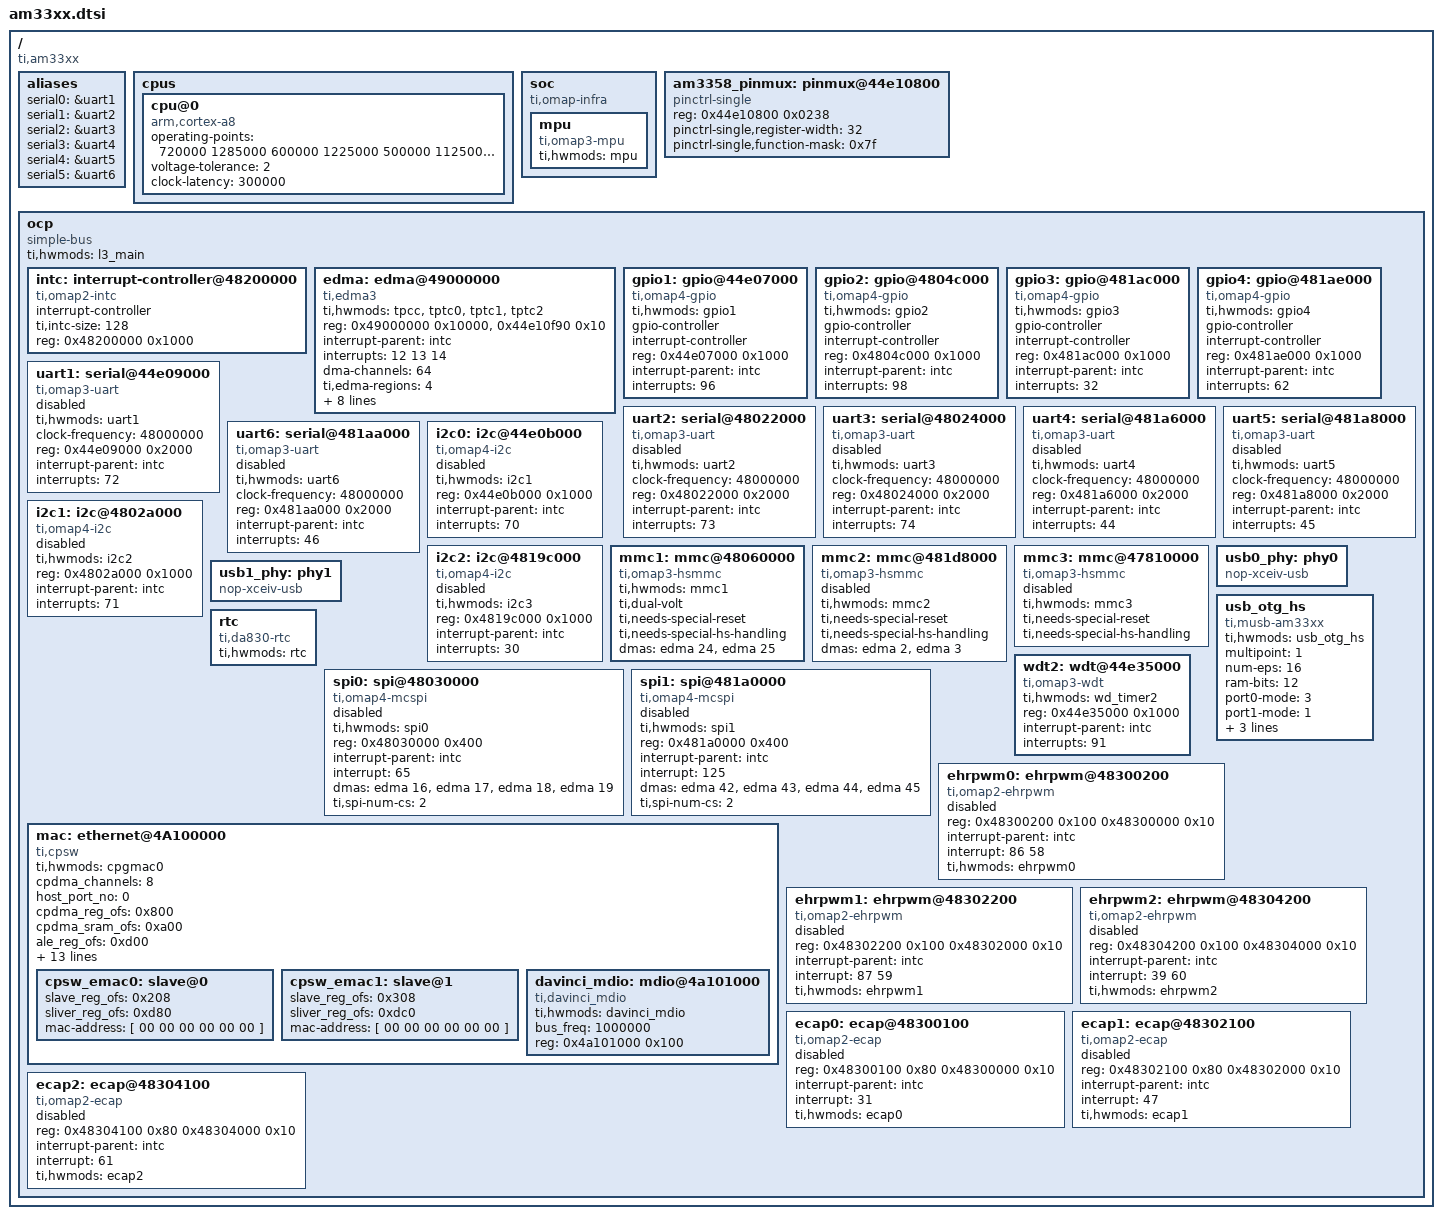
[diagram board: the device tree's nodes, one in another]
/*
 * Device Tree Source for AM33XX SoC
 *
 * Copyright (C) 2012 Texas Instruments Incorporated - http://www.ti.com/
 *
 * This file is licensed under the terms of the GNU General Public License
 * version 2.  This program is licensed "as is" without any warranty of any
 * kind, whether express or implied.
 */

/include/ "skeleton.dtsi"

/ {
	compatible = "ti,am33xx";

	aliases {
		serial0 = &uart1;
		serial1 = &uart2;
		serial2 = &uart3;
		serial3 = &uart4;
		serial4 = &uart5;
		serial5 = &uart6;
	};

	cpus {
		cpu@0 {
			compatible = "arm,cortex-a8";

			/*
			 * To consider voltage drop between PMIC and SoC,
			 * tolerance value is reduced to 2% from 4% and
			 * voltage value is increased as a precaution.
			 */
			operating-points = <
				/* kHz    uV */
				720000  1285000
				600000  1225000
				500000  1125000
				275000  1125000
			>;
			voltage-tolerance = <2>; /* 2 percentage */
			clock-latency = <300000>; /* From omap-cpufreq driver */
		};
	};

	/*
	 * The soc node represents the soc top level view. It is uses for IPs
	 * that are not memory mapped in the MPU view or for the MPU itself.
	 */
	soc {
		compatible = "ti,omap-infra";
		mpu {
			compatible = "ti,omap3-mpu";
			ti,hwmods = "mpu";
		};
	};

	am3358_pinmux: pinmux@44e10800 {
		compatible = "pinctrl-single";
		reg = <0x44e10800 0x0238>;
		#address-cells = <1>;
		#size-cells = <0>;
		pinctrl-single,register-width = <32>;
		pinctrl-single,function-mask = <0x7f>;
	};

	/*
	 * XXX: Use a flat representation of the AM33XX interconnect.
	 * The real AM33XX interconnect network is quite complex.Since
	 * that will not bring real advantage to represent that in DT
	 * for the moment, just use a fake OCP bus entry to represent
	 * the whole bus hierarchy.
	 */
	ocp {
		compatible = "simple-bus";
		#address-cells = <1>;
		#size-cells = <1>;
		ranges;
		ti,hwmods = "l3_main";

		intc: interrupt-controller@48200000 {
			compatible = "ti,omap2-intc";
			interrupt-controller;
			#interrupt-cells = <1>;
			ti,intc-size = <128>;
			reg = <0x48200000 0x1000>;
		};

		edma: edma@49000000 {
			compatible = "ti,edma3";
			ti,hwmods = "tpcc", "tptc0", "tptc1", "tptc2";
			reg =	<0x49000000 0x10000>,
				<0x44e10f90 0x10>;
			interrupt-parent = <&intc>;
			interrupts = <12 13 14>;
			#dma-cells = <1>;
			dma-channels = <64>;
			ti,edma-regions = <4>;
			ti,edma-slots = <256>;
			ti,edma-reserved-channels = <0  2
						     14 2
						     26 6
						     48 4
						     56 8>;
			ti,edma-reserved-slots = <0  2
						  14 2
						  26 6
						  48 4
						  56 8
						  64 127>;
			ti,edma-queue-tc-map = <0 0
						1 1
						2 2>;
			ti,edma-queue-priority-map = <0 0
						      1 1
						      2 2>;
			ti,edma-default-queue = <0>;
		};

		gpio1: gpio@44e07000 {
			compatible = "ti,omap4-gpio";
			ti,hwmods = "gpio1";
			gpio-controller;
			#gpio-cells = <2>;
			interrupt-controller;
			#interrupt-cells = <1>;
			reg = <0x44e07000 0x1000>;
			interrupt-parent = <&intc>;
			interrupts = <96>;
		};

		gpio2: gpio@4804c000 {
			compatible = "ti,omap4-gpio";
			ti,hwmods = "gpio2";
			gpio-controller;
			#gpio-cells = <2>;
			interrupt-controller;
			#interrupt-cells = <1>;
			reg = <0x4804c000 0x1000>;
			interrupt-parent = <&intc>;
			interrupts = <98>;
		};

		gpio3: gpio@481ac000 {
			compatible = "ti,omap4-gpio";
			ti,hwmods = "gpio3";
			gpio-controller;
			#gpio-cells = <2>;
			interrupt-controller;
			#interrupt-cells = <1>;
			reg = <0x481ac000 0x1000>;
			interrupt-parent = <&intc>;
			interrupts = <32>;
		};

		gpio4: gpio@481ae000 {
			compatible = "ti,omap4-gpio";
			ti,hwmods = "gpio4";
			gpio-controller;
			#gpio-cells = <2>;
			interrupt-controller;
			#interrupt-cells = <1>;
			reg = <0x481ae000 0x1000>;
			interrupt-parent = <&intc>;
			interrupts = <62>;
		};

		uart1: serial@44e09000 {
			compatible = "ti,omap3-uart";
			ti,hwmods = "uart1";
			clock-frequency = <48000000>;
			reg = <0x44e09000 0x2000>;
			interrupt-parent = <&intc>;
			interrupts = <72>;
			status = "disabled";
		};

		uart2: serial@48022000 {
			compatible = "ti,omap3-uart";
			ti,hwmods = "uart2";
			clock-frequency = <48000000>;
			reg = <0x48022000 0x2000>;
			interrupt-parent = <&intc>;
			interrupts = <73>;
			status = "disabled";
		};

		uart3: serial@48024000 {
			compatible = "ti,omap3-uart";
			ti,hwmods = "uart3";
			clock-frequency = <48000000>;
			reg = <0x48024000 0x2000>;
			interrupt-parent = <&intc>;
			interrupts = <74>;
			status = "disabled";
		};

		uart4: serial@481a6000 {
			compatible = "ti,omap3-uart";
			ti,hwmods = "uart4";
			clock-frequency = <48000000>;
			reg = <0x481a6000 0x2000>;
			interrupt-parent = <&intc>;
			interrupts = <44>;
			status = "disabled";
		};

		uart5: serial@481a8000 {
			compatible = "ti,omap3-uart";
			ti,hwmods = "uart5";
			clock-frequency = <48000000>;
			reg = <0x481a8000 0x2000>;
			interrupt-parent = <&intc>;
			interrupts = <45>;
			status = "disabled";
		};

		uart6: serial@481aa000 {
			compatible = "ti,omap3-uart";
			ti,hwmods = "uart6";
			clock-frequency = <48000000>;
			reg = <0x481aa000 0x2000>;
			interrupt-parent = <&intc>;
			interrupts = <46>;
			status = "disabled";
		};

		i2c0: i2c@44e0b000 {
			compatible = "ti,omap4-i2c";
			#address-cells = <1>;
			#size-cells = <0>;
			ti,hwmods = "i2c1";	/* TODO: Fix hwmod */
			reg = <0x44e0b000 0x1000>;
			interrupt-parent = <&intc>;
			interrupts = <70>;
			status = "disabled";
		};

		i2c1: i2c@4802a000 {
			compatible = "ti,omap4-i2c";
			#address-cells = <1>;
			#size-cells = <0>;
			ti,hwmods = "i2c2";	/* TODO: Fix hwmod */
			reg = <0x4802a000 0x1000>;
			interrupt-parent = <&intc>;
			interrupts = <71>;
			status = "disabled";
		};

		i2c2: i2c@4819c000 {
			compatible = "ti,omap4-i2c";
			#address-cells = <1>;
			#size-cells = <0>;
			ti,hwmods = "i2c3";	/* TODO: Fix hwmod */
			reg = <0x4819c000 0x1000>;
			interrupt-parent = <&intc>;
			interrupts = <30>;
			status = "disabled";
		};

		mmc1: mmc@48060000 {
			compatible = "ti,omap3-hsmmc";
			ti,hwmods = "mmc1";
			ti,dual-volt;
			ti,needs-special-reset;
			ti,needs-special-hs-handling;
			dmas = <&edma 24
				&edma 25>;
			dma-names = "tx", "rx";
		};

		mmc2: mmc@481d8000 {
			compatible = "ti,omap3-hsmmc";
			ti,hwmods = "mmc2";
			ti,needs-special-reset;
			ti,needs-special-hs-handling;
			dmas = <&edma 2
				&edma 3>;
			dma-names = "tx", "rx";
			status = "disabled";
		};

		mmc3: mmc@47810000 {
			compatible = "ti,omap3-hsmmc";
			ti,hwmods = "mmc3";
			ti,needs-special-reset;
			ti,needs-special-hs-handling;
			status = "disabled";
		};

		usb0_phy: phy0 {
			compatible = "nop-xceiv-usb";
		};

		usb1_phy: phy1 {
			compatible = "nop-xceiv-usb";
		};

		usb_otg_hs: usb_otg_hs {
			compatible = "ti,musb-am33xx";
			ti,hwmods = "usb_otg_hs";
			multipoint = <1>;
			num-eps = <16>;
			ram-bits = <12>;
			port0-mode = <3>;
			port1-mode = <1>;
			power = <250>;
			usb0-phy = <&usb0_phy>;
			usb1-phy = <&usb1_phy>;
		};

		rtc {
			compatible = "ti,da830-rtc";
			ti,hwmods = "rtc";
		};

		spi0: spi@48030000 {
			compatible = "ti,omap4-mcspi";
			ti,hwmods = "spi0";
			#address-cells = <1>;
			#size-cells = <0>;
			reg = <0x48030000 0x400>;
			interrupt-parent = <&intc>;
			interrupt = <65>;
			dmas = <&edma 16
				&edma 17
				&edma 18
				&edma 19>;
			dma-names = "tx0", "rx0", "tx1", "rx1";
			ti,spi-num-cs = <2>;
			status = "disabled";
		};

		spi1: spi@481a0000 {
			compatible = "ti,omap4-mcspi";
			ti,hwmods = "spi1";
			#address-cells = <1>;
			#size-cells = <0>;
			reg = <0x481a0000 0x400>;
			interrupt-parent = <&intc>;
			interrupt = <125>;
			dmas = <&edma 42
				&edma 43
				&edma 44
				&edma 45>;
			dma-names = "tx0", "rx0", "tx1", "rx1";
			ti,spi-num-cs = <2>;
			status = "disabled";
		};

		wdt2: wdt@44e35000 {
			compatible = "ti,omap3-wdt";
			ti,hwmods = "wd_timer2";
			reg = <0x44e35000 0x1000>;
			interrupt-parent = <&intc>;
			interrupts = <91>;
		};

		mac: ethernet@4A100000 {
			compatible = "ti,cpsw";
			ti,hwmods = "cpgmac0";
			cpdma_channels = <8>;
			host_port_no = <0>;
			cpdma_reg_ofs = <0x800>;
			cpdma_sram_ofs = <0xa00>;
			ale_reg_ofs = <0xd00>;
			ale_entries = <1024>;
			host_port_reg_ofs = <0x108>;
			hw_stats_reg_ofs = <0x900>;
			bd_ram_ofs = <0x2000>;
			bd_ram_size = <0x2000>;
			no_bd_ram = <0>;
			rx_descs = <64>;
			mac_control = <0x20>;
			slaves = <2>;
			reg = <0x4a100000 0x800
				0x4a101200 0x100
				0x4a101000 0x100>;
			#address-cells = <1>;
			#size-cells = <1>;
			interrupt-parent = <&intc>;
			/* c0_rx_thresh_pend c0_rx_pend c0_tx_pend c0_misc_pend*/
			interrupts = <40 41 42 43>;
			ranges;
			cpsw_emac0: slave@0 {
				slave_reg_ofs = <0x208>;
				sliver_reg_ofs = <0xd80>;
				/* Filled in by U-Boot */
				mac-address = [ 00 00 00 00 00 00 ];
			};
			cpsw_emac1: slave@1 {
				slave_reg_ofs = <0x308>;
				sliver_reg_ofs = <0xdc0>;
				/* Filled in by U-Boot */
				mac-address = [ 00 00 00 00 00 00 ];
			};

			davinci_mdio: mdio@4a101000 {
				compatible = "ti,davinci_mdio";
				#address-cells = <1>;
				#size-cells = <0>;
				ti,hwmods = "davinci_mdio";
				bus_freq = <1000000>;
				reg = <0x4a101000 0x100>;
			};

		};

		ehrpwm0: ehrpwm@48300200 {
			compatible	= "ti,omap2-ehrpwm";
			reg = <0x48300200 0x100 0x48300000 0x10>;
			interrupt-parent = <&intc>;
			interrupt = <86 58>;
			ti,hwmods = "ehrpwm0";
			#pwm-cells = <3>;
			status = "disabled";
		};

		ehrpwm1: ehrpwm@48302200 {
			compatible	= "ti,omap2-ehrpwm";
			reg = <0x48302200 0x100 0x48302000 0x10>;
			interrupt-parent = <&intc>;
			interrupt = <87 59>;
			ti,hwmods = "ehrpwm1";
			#pwm-cells = <3>;
			status = "disabled";
		};

		ehrpwm2: ehrpwm@48304200 {
			compatible	= "ti,omap2-ehrpwm";
			reg = <0x48304200 0x100 0x48304000 0x10>;
			interrupt-parent = <&intc>;
			interrupt = <39 60>;
			ti,hwmods = "ehrpwm2";
			#pwm-cells = <3>;
			status = "disabled";
		};

		ecap0: ecap@48300100 {
			compatible	= "ti,omap2-ecap";
			reg = <0x48300100 0x80 0x48300000 0x10>;
			interrupt-parent = <&intc>;
			interrupt = <31>;
			ti,hwmods = "ecap0";
			#pwm-cells = <3>;
			status = "disabled";
		};

		ecap1: ecap@48302100 {
			compatible	= "ti,omap2-ecap";
			reg = <0x48302100 0x80 0x48302000 0x10>;
			interrupt-parent = <&intc>;
			interrupt = <47>;
			ti,hwmods = "ecap1";
			#pwm-cells = <3>;
			status = "disabled";
		};

		ecap2: ecap@48304100 {
			compatible	= "ti,omap2-ecap";
			reg = <0x48304100 0x80 0x48304000 0x10>;
			interrupt-parent = <&intc>;
			interrupt = <61>;
			ti,hwmods = "ecap2";
			#pwm-cells = <3>;
			status = "disabled";
		};
	};
};
